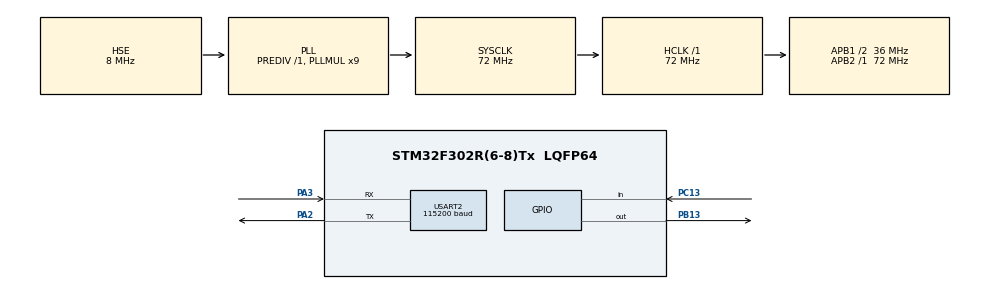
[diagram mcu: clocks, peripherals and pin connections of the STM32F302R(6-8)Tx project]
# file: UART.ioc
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Mcu.Family=STM32F3
Mcu.Name=STM32F302R(6-8)Tx
Mcu.Package=LQFP64
NVIC.PriorityGroup=NVIC_PRIORITYGROUP_0
NVIC.USART2_IRQn=true\:0\:0\:false\:false\:true\:true\:true\:true
PA13.Mode=Serial_Wire
PA13.Signal=SYS_JTMS-SWDIO
PA14.Mode=Serial_Wire
PA14.Signal=SYS_JTCK-SWCLK
PA2.Mode=Asynchronous
PA2.Signal=USART2_TX
PA3.Mode=Asynchronous
PA3.Signal=USART2_RX
PB13.Signal=GPIO_Output
PC13.Signal=GPIO_Input
PF0-OSC_IN.Mode=HSE-External-Oscillator
PF0-OSC_IN.Signal=RCC_OSC_IN
PF1-OSC_OUT.Mode=HSE-External-Oscillator
PF1-OSC_OUT.Signal=RCC_OSC_OUT
ProjectManager.HeapSize=0x200
ProjectManager.StackSize=0x400
ProjectManager.TargetToolchain=STM32CubeIDE
RCC.AHBFreq_Value=72000000
RCC.APB1CLKDivider=RCC_HCLK_DIV2
RCC.APB1Freq_Value=36000000
RCC.APB1TimFreq_Value=72000000
RCC.APB2Freq_Value=72000000
RCC.APB2TimFreq_Value=72000000
RCC.CortexFreq_Value=72000000
RCC.HCLKFreq_Value=72000000
RCC.HSE_VALUE=8000000
RCC.HSI_VALUE=8000000
RCC.PLLM=8
RCC.PLLMUL=RCC_PLL_MUL9
RCC.PLLN=336
RCC.PLLP=RCC_PLLP_DIV4
RCC.PLLQ=7
RCC.PLLSourceVirtual=RCC_PLLSOURCE_HSE
RCC.SYSCLKFreq_VALUE=72000000
RCC.SYSCLKSourceVirtual=RCC_SYSCLKSOURCE_PLLCLK
RCC.USBFreq_Value=72000000
USART2.BaudRate=115200
USART2.VirtualMode-Asynchronous=VM_ASYNC
board=NUCLEO-F302R8

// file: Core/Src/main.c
/* USER CODE BEGIN Header */
/**
 ******************************************************************************
 * @file           : main.c
 * @brief          : Main program body
 ******************************************************************************
 * @attention
 *
 * Copyright (c) 2023 STMicroelectronics.
 * All rights reserved.
 *
 * This software is licensed under terms that can be found in the LICENSE file
 * in the root directory of this software component.
 * If no LICENSE file comes with this software, it is provided AS-IS.
 *
 ******************************************************************************
 */
/* USER CODE END Header */
#include "main.h"

UART_HandleTypeDef huart2;

/* USER CODE BEGIN PV */
//uint8_t tx_buffer[27] = "Welcome Angel!\n\r";
//uint8_t rx_indx;
//uint8_t rx_data[2];
//uint8_t rx_buffer[100];
//uint8_t transfer_cplt;

uint8_t RX1_Char = 0x00;
/* USER CODE END PV */

void SystemClock_Config(void);
static void MX_GPIO_Init(void);
static void MX_USART2_UART_Init(void);

/* USER CODE BEGIN 0 */
//---------[ UART Data Reception Completion CallBackFunc. ]---------
//void HAL_USART_RxCpltCallback(UART_HandleTypeDef *huart) {
// HAL_UART_Receive_IT(&huart2, &RX1_Char, 1);
// }
/* USER CODE END 0 */

int main(void) {
	/* USER CODE BEGIN 1 */
    uint8_t MSG1[] = "Button State: Released\r\n";
	uint8_t MSG2[] = "Button State: Pressed\r\n";
	/* USER CODE END 1 */

	/* MCU Configuration--------------------------------------------------------*/

	/* Reset of all peripherals, Initializes the Flash interface and the Systick. */
	HAL_Init();

	/* Configure the system clock */
	SystemClock_Config();

	/* Initialize all configured peripherals */
	MX_GPIO_Init();
	MX_USART2_UART_Init();
	HAL_UART_Receive_IT(&huart2, &RX1_Char, 1);
	 // HAL_UART_Receive_IT(&huart2, rx_data, 1);

	/* Infinite loop */
	while (1) {
		 //--------[ Read The Button State & Send It Via UART ]---------
		 if(HAL_GPIO_ReadPin (GPIOC, GPIO_PIN_13))
		 {
		 HAL_UART_Transmit(&huart2, MSG2, sizeof(MSG2), 100);
		 }
		 else
		 {
		 HAL_UART_Transmit(&huart2, MSG1, sizeof(MSG1), 100);
		 }
		 //--------[ Read The Received Character & Toggle LEDs Accordingly ]--------
		 if(RX1_Char == '1')
		 {
		 HAL_GPIO_TogglePin(GPIOB, GPIO_PIN_13);
		 HAL_UART_Receive_IT(&huart2, &RX1_Char, 1);
		 RX1_Char = 0x00;
		 }
		 if(RX1_Char == '2')
		 {
		 HAL_GPIO_TogglePin(GPIOB, GPIO_PIN_13);
		 HAL_UART_Receive_IT(&huart2, &RX1_Char, 1);
		 RX1_Char = 0x00;
		 }
		 HAL_Delay(100);
		// ---------------------------------------//
		//  HAL_UART_Transmit(&huart2, tx_buffer, 27, 10);
		//  HAL_Delay(1000);
		/* USER CODE BEGIN 3 */
		//--------------------------------------------------------//
	}
	/* USER CODE END 3 */
}

void SystemClock_Config(void) {
	RCC_OscInitTypeDef RCC_OscInitStruct = { 0 };
	RCC_ClkInitTypeDef RCC_ClkInitStruct = { 0 };

	/** Initializes the RCC Oscillators according to the specified parameters
	 * in the RCC_OscInitTypeDef structure.
	 */
	RCC_OscInitStruct.OscillatorType = RCC_OSCILLATORTYPE_HSE;
	RCC_OscInitStruct.HSEState = RCC_HSE_ON;
	RCC_OscInitStruct.HSEPredivValue = RCC_HSE_PREDIV_DIV1;
	RCC_OscInitStruct.HSIState = RCC_HSI_ON;
	RCC_OscInitStruct.PLL.PLLState = RCC_PLL_ON;
	RCC_OscInitStruct.PLL.PLLSource = RCC_PLLSOURCE_HSE;
	RCC_OscInitStruct.PLL.PLLMUL = RCC_PLL_MUL9;
	if (HAL_RCC_OscConfig(&RCC_OscInitStruct) != HAL_OK) {
		Error_Handler();
	}

	/** Initializes the CPU, AHB and APB buses clocks
	 */
	RCC_ClkInitStruct.ClockType = RCC_CLOCKTYPE_HCLK | RCC_CLOCKTYPE_SYSCLK
			| RCC_CLOCKTYPE_PCLK1 | RCC_CLOCKTYPE_PCLK2;
	RCC_ClkInitStruct.SYSCLKSource = RCC_SYSCLKSOURCE_PLLCLK;
	RCC_ClkInitStruct.AHBCLKDivider = RCC_SYSCLK_DIV1;
	RCC_ClkInitStruct.APB1CLKDivider = RCC_HCLK_DIV2;
	RCC_ClkInitStruct.APB2CLKDivider = RCC_HCLK_DIV1;

	if (HAL_RCC_ClockConfig(&RCC_ClkInitStruct, FLASH_LATENCY_2) != HAL_OK) {
		Error_Handler();
	}
}

static void MX_USART2_UART_Init(void) {

	huart2.Instance = USART2;
	huart2.Init.BaudRate = 115200;
	huart2.Init.WordLength = UART_WORDLENGTH_8B;
	huart2.Init.StopBits = UART_STOPBITS_1;
	huart2.Init.Parity = UART_PARITY_NONE;
	huart2.Init.Mode = UART_MODE_TX_RX;
	huart2.Init.HwFlowCtl = UART_HWCONTROL_NONE;
	huart2.Init.OverSampling = UART_OVERSAMPLING_16;
	huart2.Init.OneBitSampling = UART_ONE_BIT_SAMPLE_DISABLE;
	huart2.AdvancedInit.AdvFeatureInit = UART_ADVFEATURE_NO_INIT;
	if (HAL_UART_Init(&huart2) != HAL_OK) {
		Error_Handler();
	}

}

static void MX_GPIO_Init(void) {
	GPIO_InitTypeDef GPIO_InitStruct = { 0 };

	/* GPIO Ports Clock Enable */
	__HAL_RCC_GPIOC_CLK_ENABLE();
	__HAL_RCC_GPIOF_CLK_ENABLE();
	__HAL_RCC_GPIOA_CLK_ENABLE();
	__HAL_RCC_GPIOB_CLK_ENABLE();

	/*Configure GPIO pin Output Level */
	HAL_GPIO_WritePin(GPIOB, GPIO_PIN_13, GPIO_PIN_RESET);

	/*Configure GPIO pin : PC13 */
	GPIO_InitStruct.Pin = GPIO_PIN_13;
	GPIO_InitStruct.Mode = GPIO_MODE_INPUT;
	GPIO_InitStruct.Pull = GPIO_NOPULL;
	HAL_GPIO_Init(GPIOC, &GPIO_InitStruct);

	/*Configure GPIO pin : PB13 */
	GPIO_InitStruct.Pin = GPIO_PIN_13;
	GPIO_InitStruct.Mode = GPIO_MODE_OUTPUT_PP;
	GPIO_InitStruct.Pull = GPIO_NOPULL;
	GPIO_InitStruct.Speed = GPIO_SPEED_FREQ_LOW;
	HAL_GPIO_Init(GPIOB, &GPIO_InitStruct);

}

/* USER CODE BEGIN 4 */
/*
void HAL_UART_RxCpltCallback(UART_HandleTypeDef *huart) {
	UNUSED(huart);
	//HAL_UART_Receive(&huart2, rx_data, 6, 10);
	uint8_t i;
	if (huart->Instance == USART2) {
		if (rx_indx == 0) {
			for (i = 0; i < 100; i++)
				rx_buffer[i] = 0;
			HAL_GPIO_WritePin(GPIOB, GPIO_PIN_13, GPIO_PIN_RESET);
		}
		if (rx_data[0] != 13) {
			rx_buffer[rx_indx++] = rx_data[0];
		} else {
			rx_indx = 0;
			transfer_cplt = 1;
			HAL_UART_Transmit(&huart2, "\n\r", 2, 100);
			if (!strcmp(rx_buffer, "LED ON")) {
				HAL_GPIO_WritePin(GPIOB, GPIO_PIN_13, GPIO_PIN_SET);
			}
		}
		HAL_UART_Receive_IT(&huart2, rx_data, 1);
		HAL_UART_Transmit(&huart2, rx_data, strlen(rx_data), 100);
	}
}
*/
/* USER CODE END 4 */

void Error_Handler(void) {
	__disable_irq();
	while (1) {
	}
}
